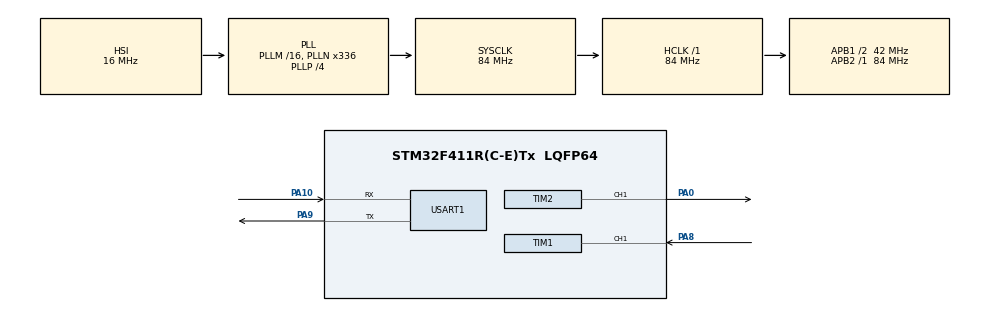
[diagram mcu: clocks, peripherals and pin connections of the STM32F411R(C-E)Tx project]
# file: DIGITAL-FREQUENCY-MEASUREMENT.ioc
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Mcu.Family=STM32F4
Mcu.Name=STM32F411R(C-E)Tx
Mcu.Package=LQFP64
NVIC.PriorityGroup=NVIC_PRIORITYGROUP_0
PA0-WKUP.Signal=S_TIM2_CH1_ETR
PA10.Mode=Asynchronous
PA10.Signal=USART1_RX
PA8.Signal=S_TIM1_CH1
PA9.Mode=Asynchronous
PA9.Signal=USART1_TX
ProjectManager.HeapSize=0x200
ProjectManager.StackSize=0x400
ProjectManager.TargetToolchain=STM32CubeIDE
RCC.48MHZClocksFreq_Value=84000000
RCC.AHBFreq_Value=84000000
RCC.APB1CLKDivider=RCC_HCLK_DIV2
RCC.APB1Freq_Value=42000000
RCC.APB1TimFreq_Value=84000000
RCC.APB2Freq_Value=84000000
RCC.APB2TimFreq_Value=84000000
RCC.CortexFreq_Value=84000000
RCC.FLatency-AdvancedSettings=FLASH_LATENCY_2
RCC.HCLKFreq_Value=84000000
RCC.HSE_VALUE=8000000
RCC.HSI_VALUE=16000000
RCC.PLLN=336
RCC.PLLP=RCC_PLLP_DIV4
RCC.SYSCLKFreq_VALUE=84000000
RCC.SYSCLKSource=RCC_SYSCLKSOURCE_PLLCLK
RCC.VCOOutputFreq_Value=336000000
SH.S_TIM1_CH1.0=TIM1_CH1,Input_Capture1_from_TI1
SH.S_TIM2_CH1_ETR.0=TIM2_CH1,Output Compare1 CH1
TIM1.Channel-Input_Capture1_from_TI1=TIM_CHANNEL_1
TIM2.Channel-Output\ Compare1\ CH1=TIM_CHANNEL_1
TIM2.Period=1000
TIM2.Prescaler=84
USART1.VirtualMode=VM_ASYNC
VP_TIM1_VS_ClockSourceINT.Mode=Internal
VP_TIM2_VS_ClockSourceINT.Mode=Internal
board=NUCLEO-F411RE

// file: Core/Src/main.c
/* USER CODE BEGIN Header */
/**
  ******************************************************************************
  * @file           : main.c
  * @brief          : Main program body
  ******************************************************************************
  * @attention
  *
  * Copyright (c) 2026 STMicroelectronics.
  * All rights reserved.
  *
  * This software is licensed under terms that can be found in the LICENSE file
  * in the root directory of this software component.
  * If no LICENSE file comes with this software, it is provided AS-IS.
  *
  ******************************************************************************
  */
/* USER CODE END Header */
#include "main.h"

/* USER CODE BEGIN Includes */
#include "string.h"
#include <stdio.h>
/* USER CODE END Includes */

TIM_HandleTypeDef htim1;
TIM_HandleTypeDef htim2;

UART_HandleTypeDef huart1;

/* USER CODE BEGIN PV */
volatile uint32_t Capture1 = 0;
volatile uint32_t Capture2 = 0;

volatile uint32_t Difference = 0;

volatile uint8_t FirstCapture = 0;

uint32_t Frequency;

/* USER CODE END PV */

void SystemClock_Config(void);
static void MX_GPIO_Init(void);
static void MX_TIM1_Init(void);
static void MX_TIM2_Init(void);
static void MX_USART1_UART_Init(void);

int main(void)
{

  /* MCU Configuration--------------------------------------------------------*/

  /* Reset of all peripherals, Initializes the Flash interface and the Systick. */
  HAL_Init();

  /* Configure the system clock */
  SystemClock_Config();

  /* Initialize all configured peripherals */
  MX_GPIO_Init();
  MX_TIM1_Init();
  MX_TIM2_Init();
  MX_USART1_UART_Init();

  /* Infinite loop */
  while (1)
  {
	  if(Capture2 >= Capture1)
	  {
	      Difference = Capture2 - Capture1;
	  }
	  else
	  {
	      Difference = (0xFFFFFFFF - Capture1) + Capture2 + 1;
	  }
	  Frequency = TimerClock / Difference;

	  sprintf(txBuf,
	          "Frequency : %lu Hz\r\n",
	          Frequency);

	  HAL_UART_Transmit(&huart1,
	                    (uint8_t*)txBuf,
	                    strlen(txBuf),
	                    HAL_MAX_DELAY);

  }
}

void SystemClock_Config(void)
{
  RCC_OscInitTypeDef RCC_OscInitStruct = {0};
  RCC_ClkInitTypeDef RCC_ClkInitStruct = {0};

  /** Configure the main internal regulator output voltage
  */
  __HAL_RCC_PWR_CLK_ENABLE();
  __HAL_PWR_VOLTAGESCALING_CONFIG(PWR_REGULATOR_VOLTAGE_SCALE1);

  /** Initializes the RCC Oscillators according to the specified parameters
  * in the RCC_OscInitTypeDef structure.
  */
  RCC_OscInitStruct.OscillatorType = RCC_OSCILLATORTYPE_HSI;
  RCC_OscInitStruct.HSIState = RCC_HSI_ON;
  RCC_OscInitStruct.HSICalibrationValue = RCC_HSICALIBRATION_DEFAULT;
  RCC_OscInitStruct.PLL.PLLState = RCC_PLL_ON;
  RCC_OscInitStruct.PLL.PLLSource = RCC_PLLSOURCE_HSI;
  RCC_OscInitStruct.PLL.PLLM = 16;
  RCC_OscInitStruct.PLL.PLLN = 336;
  RCC_OscInitStruct.PLL.PLLP = RCC_PLLP_DIV4;
  RCC_OscInitStruct.PLL.PLLQ = 4;
  if (HAL_RCC_OscConfig(&RCC_OscInitStruct) != HAL_OK)
  {
    Error_Handler();
  }

  /** Initializes the CPU, AHB and APB buses clocks
  */
  RCC_ClkInitStruct.ClockType = RCC_CLOCKTYPE_HCLK|RCC_CLOCKTYPE_SYSCLK
                              |RCC_CLOCKTYPE_PCLK1|RCC_CLOCKTYPE_PCLK2;
  RCC_ClkInitStruct.SYSCLKSource = RCC_SYSCLKSOURCE_PLLCLK;
  RCC_ClkInitStruct.AHBCLKDivider = RCC_SYSCLK_DIV1;
  RCC_ClkInitStruct.APB1CLKDivider = RCC_HCLK_DIV2;
  RCC_ClkInitStruct.APB2CLKDivider = RCC_HCLK_DIV1;

  if (HAL_RCC_ClockConfig(&RCC_ClkInitStruct, FLASH_LATENCY_2) != HAL_OK)
  {
    Error_Handler();
  }
}

static void MX_TIM1_Init(void)
{

  TIM_ClockConfigTypeDef sClockSourceConfig = {0};
  TIM_MasterConfigTypeDef sMasterConfig = {0};
  TIM_IC_InitTypeDef sConfigIC = {0};

  htim1.Instance = TIM1;
  htim1.Init.Prescaler = 0;
  htim1.Init.CounterMode = TIM_COUNTERMODE_UP;
  htim1.Init.Period = 65535;
  htim1.Init.ClockDivision = TIM_CLOCKDIVISION_DIV1;
  htim1.Init.RepetitionCounter = 0;
  htim1.Init.AutoReloadPreload = TIM_AUTORELOAD_PRELOAD_DISABLE;
  if (HAL_TIM_Base_Init(&htim1) != HAL_OK)
  {
    Error_Handler();
  }
  sClockSourceConfig.ClockSource = TIM_CLOCKSOURCE_INTERNAL;
  if (HAL_TIM_ConfigClockSource(&htim1, &sClockSourceConfig) != HAL_OK)
  {
    Error_Handler();
  }
  if (HAL_TIM_IC_Init(&htim1) != HAL_OK)
  {
    Error_Handler();
  }
  sMasterConfig.MasterOutputTrigger = TIM_TRGO_RESET;
  sMasterConfig.MasterSlaveMode = TIM_MASTERSLAVEMODE_DISABLE;
  if (HAL_TIMEx_MasterConfigSynchronization(&htim1, &sMasterConfig) != HAL_OK)
  {
    Error_Handler();
  }
  sConfigIC.ICPolarity = TIM_INPUTCHANNELPOLARITY_RISING;
  sConfigIC.ICSelection = TIM_ICSELECTION_DIRECTTI;
  sConfigIC.ICPrescaler = TIM_ICPSC_DIV1;
  sConfigIC.ICFilter = 0;
  if (HAL_TIM_IC_ConfigChannel(&htim1, &sConfigIC, TIM_CHANNEL_1) != HAL_OK)
  {
    Error_Handler();
  }

}

static void MX_TIM2_Init(void)
{

  TIM_ClockConfigTypeDef sClockSourceConfig = {0};
  TIM_MasterConfigTypeDef sMasterConfig = {0};
  TIM_OC_InitTypeDef sConfigOC = {0};

  htim2.Instance = TIM2;
  htim2.Init.Prescaler = 84;
  htim2.Init.CounterMode = TIM_COUNTERMODE_UP;
  htim2.Init.Period = 1000;
  htim2.Init.ClockDivision = TIM_CLOCKDIVISION_DIV1;
  htim2.Init.AutoReloadPreload = TIM_AUTORELOAD_PRELOAD_DISABLE;
  if (HAL_TIM_Base_Init(&htim2) != HAL_OK)
  {
    Error_Handler();
  }
  sClockSourceConfig.ClockSource = TIM_CLOCKSOURCE_INTERNAL;
  if (HAL_TIM_ConfigClockSource(&htim2, &sClockSourceConfig) != HAL_OK)
  {
    Error_Handler();
  }
  if (HAL_TIM_OC_Init(&htim2) != HAL_OK)
  {
    Error_Handler();
  }
  sMasterConfig.MasterOutputTrigger = TIM_TRGO_RESET;
  sMasterConfig.MasterSlaveMode = TIM_MASTERSLAVEMODE_DISABLE;
  if (HAL_TIMEx_MasterConfigSynchronization(&htim2, &sMasterConfig) != HAL_OK)
  {
    Error_Handler();
  }
  sConfigOC.OCMode = TIM_OCMODE_TIMING;
  sConfigOC.Pulse = 0;
  sConfigOC.OCPolarity = TIM_OCPOLARITY_HIGH;
  sConfigOC.OCFastMode = TIM_OCFAST_DISABLE;
  if (HAL_TIM_OC_ConfigChannel(&htim2, &sConfigOC, TIM_CHANNEL_1) != HAL_OK)
  {
    Error_Handler();
  }
  HAL_TIM_MspPostInit(&htim2);

}

static void MX_USART1_UART_Init(void)
{

  huart1.Instance = USART1;
  huart1.Init.BaudRate = 115200;
  huart1.Init.WordLength = UART_WORDLENGTH_8B;
  huart1.Init.StopBits = UART_STOPBITS_1;
  huart1.Init.Parity = UART_PARITY_NONE;
  huart1.Init.Mode = UART_MODE_TX_RX;
  huart1.Init.HwFlowCtl = UART_HWCONTROL_NONE;
  huart1.Init.OverSampling = UART_OVERSAMPLING_16;
  if (HAL_UART_Init(&huart1) != HAL_OK)
  {
    Error_Handler();
  }

}

static void MX_GPIO_Init(void)
{

  /* GPIO Ports Clock Enable */
  __HAL_RCC_GPIOA_CLK_ENABLE();

}

void Error_Handler(void)
{
  __disable_irq();
  while (1)
  {
  }
}
